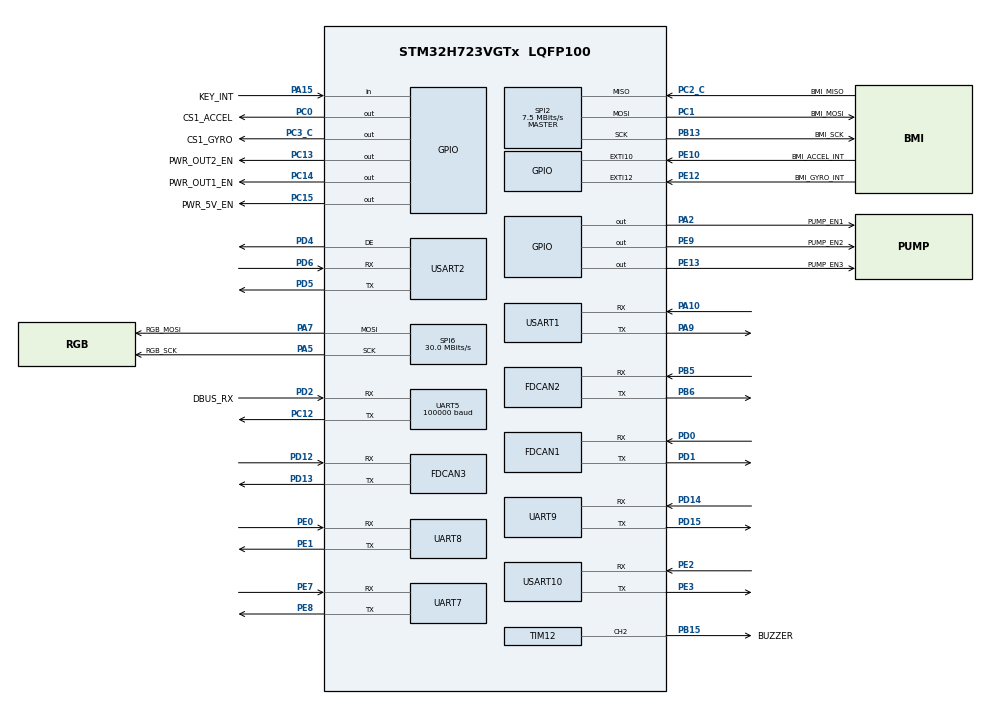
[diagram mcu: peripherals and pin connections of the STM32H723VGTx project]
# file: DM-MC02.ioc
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CORTEX_M7.CPU_DCache=Disabled
CORTEX_M7.CPU_ICache=Enabled
CORTEX_M7.Enable-Cortex_Memory_Protection_Unit_Region0_Settings=MPU_REGION_ENABLE
CORTEX_M7.MPU_Control=__NULL
CORTEX_M7.default_mode_Activation=0
Dma.Request0=SPI2_RX
Dma.Request1=SPI2_TX
Dma.Request10=UART8_TX
Dma.Request11=UART9_RX
Dma.Request12=UART9_TX
Dma.Request2=USART10_RX
Dma.Request3=USART10_TX
Dma.Request4=UART5_RX
Dma.Request5=USART1_RX
Dma.Request6=USART1_TX
Dma.Request7=UART7_RX
Dma.Request8=UART7_TX
Dma.Request9=UART8_RX
Dma.SPI2_RX.0.Direction=DMA_PERIPH_TO_MEMORY
Dma.SPI2_RX.0.EventEnable=DISABLE
Dma.SPI2_RX.0.FIFOMode=DMA_FIFOMODE_DISABLE
Dma.SPI2_RX.0.Instance=DMA1_Stream1
Dma.SPI2_RX.0.MemDataAlignment=DMA_MDATAALIGN_BYTE
Dma.SPI2_RX.0.MemInc=DMA_MINC_ENABLE
Dma.SPI2_RX.0.Mode=DMA_NORMAL
Dma.SPI2_RX.0.PeriphDataAlignment=DMA_PDATAALIGN_BYTE
Dma.SPI2_RX.0.PeriphInc=DMA_PINC_DISABLE
Dma.SPI2_RX.0.Polarity=HAL_DMAMUX_REQ_GEN_RISING
Dma.SPI2_RX.0.Priority=DMA_PRIORITY_VERY_HIGH
Dma.SPI2_RX.0.RequestNumber=1
Dma.SPI2_RX.0.SignalID=NONE
Dma.SPI2_RX.0.SyncEnable=DISABLE
Dma.SPI2_RX.0.SyncPolarity=HAL_DMAMUX_SYNC_NO_EVENT
Dma.SPI2_RX.0.SyncRequestNumber=1
Dma.SPI2_RX.0.SyncSignalID=NONE
Dma.SPI2_TX.1.Direction=DMA_MEMORY_TO_PERIPH
Dma.SPI2_TX.1.EventEnable=DISABLE
Dma.SPI2_TX.1.FIFOMode=DMA_FIFOMODE_DISABLE
Dma.SPI2_TX.1.Instance=DMA1_Stream2
Dma.SPI2_TX.1.MemDataAlignment=DMA_MDATAALIGN_BYTE
Dma.SPI2_TX.1.MemInc=DMA_MINC_ENABLE
Dma.SPI2_TX.1.Mode=DMA_NORMAL
Dma.SPI2_TX.1.PeriphDataAlignment=DMA_PDATAALIGN_BYTE
Dma.SPI2_TX.1.PeriphInc=DMA_PINC_DISABLE
Dma.SPI2_TX.1.Polarity=HAL_DMAMUX_REQ_GEN_RISING
Dma.SPI2_TX.1.Priority=DMA_PRIORITY_MEDIUM
Dma.SPI2_TX.1.RequestNumber=1
Dma.SPI2_TX.1.SignalID=NONE
Dma.SPI2_TX.1.SyncEnable=DISABLE
Dma.SPI2_TX.1.SyncPolarity=HAL_DMAMUX_SYNC_NO_EVENT
Dma.SPI2_TX.1.SyncRequestNumber=1
Dma.SPI2_TX.1.SyncSignalID=NONE
Dma.UART5_RX.4.Direction=DMA_PERIPH_TO_MEMORY
Dma.UART5_RX.4.EventEnable=DISABLE
Dma.UART5_RX.4.FIFOMode=DMA_FIFOMODE_DISABLE
Dma.UART5_RX.4.Instance=DMA1_Stream0
Dma.UART5_RX.4.MemDataAlignment=DMA_MDATAALIGN_BYTE
Dma.UART5_RX.4.MemInc=DMA_MINC_ENABLE
Dma.UART5_RX.4.Mode=DMA_CIRCULAR
Dma.UART5_RX.4.PeriphDataAlignment=DMA_PDATAALIGN_BYTE
Dma.UART5_RX.4.PeriphInc=DMA_PINC_DISABLE
Dma.UART5_RX.4.Polarity=HAL_DMAMUX_REQ_GEN_RISING
Dma.UART5_RX.4.Priority=DMA_PRIORITY_LOW
Dma.UART5_RX.4.RequestNumber=1
Dma.UART5_RX.4.SignalID=NONE
Dma.UART5_RX.4.SyncEnable=DISABLE
Dma.UART5_RX.4.SyncPolarity=HAL_DMAMUX_SYNC_NO_EVENT
Dma.UART5_RX.4.SyncRequestNumber=1
Dma.UART5_RX.4.SyncSignalID=NONE
Dma.UART7_RX.7.Direction=DMA_PERIPH_TO_MEMORY
Dma.UART7_RX.7.EventEnable=DISABLE
Dma.UART7_RX.7.FIFOMode=DMA_FIFOMODE_DISABLE
Dma.UART7_RX.7.Instance=DMA1_Stream7
Dma.UART7_RX.7.MemDataAlignment=DMA_MDATAALIGN_BYTE
Dma.UART7_RX.7.MemInc=DMA_MINC_ENABLE
Dma.UART7_RX.7.Mode=DMA_CIRCULAR
Dma.UART7_RX.7.PeriphDataAlignment=DMA_PDATAALIGN_BYTE
Dma.UART7_RX.7.PeriphInc=DMA_PINC_DISABLE
Dma.UART7_RX.7.Polarity=HAL_DMAMUX_REQ_GEN_RISING
Dma.UART7_RX.7.Priority=DMA_PRIORITY_VERY_HIGH
Dma.UART7_RX.7.RequestNumber=1
Dma.UART7_RX.7.SignalID=NONE
Dma.UART7_RX.7.SyncEnable=DISABLE
Dma.UART7_RX.7.SyncPolarity=HAL_DMAMUX_SYNC_NO_EVENT
Dma.UART7_RX.7.SyncRequestNumber=1
Dma.UART7_RX.7.SyncSignalID=NONE
Dma.UART7_TX.8.Direction=DMA_MEMORY_TO_PERIPH
Dma.UART7_TX.8.EventEnable=DISABLE
Dma.UART7_TX.8.FIFOMode=DMA_FIFOMODE_DISABLE
Dma.UART7_TX.8.Instance=DMA2_Stream0
Dma.UART7_TX.8.MemDataAlignment=DMA_MDATAALIGN_BYTE
Dma.UART7_TX.8.MemInc=DMA_MINC_ENABLE
Dma.UART7_TX.8.Mode=DMA_NORMAL
Dma.UART7_TX.8.PeriphDataAlignment=DMA_PDATAALIGN_BYTE
Dma.UART7_TX.8.PeriphInc=DMA_PINC_DISABLE
Dma.UART7_TX.8.Polarity=HAL_DMAMUX_REQ_GEN_RISING
Dma.UART7_TX.8.Priority=DMA_PRIORITY_VERY_HIGH
Dma.UART7_TX.8.RequestNumber=1
Dma.UART7_TX.8.SignalID=NONE
Dma.UART7_TX.8.SyncEnable=DISABLE
Dma.UART7_TX.8.SyncPolarity=HAL_DMAMUX_SYNC_NO_EVENT
Dma.UART7_TX.8.SyncRequestNumber=1
Dma.UART7_TX.8.SyncSignalID=NONE
Dma.UART8_RX.9.Direction=DMA_PERIPH_TO_MEMORY
Dma.UART8_RX.9.EventEnable=DISABLE
Dma.UART8_RX.9.FIFOMode=DMA_FIFOMODE_DISABLE
Dma.UART8_RX.9.Instance=DMA2_Stream1
Dma.UART8_RX.9.MemDataAlignment=DMA_MDATAALIGN_BYTE
Dma.UART8_RX.9.MemInc=DMA_MINC_ENABLE
Dma.UART8_RX.9.Mode=DMA_CIRCULAR
Dma.UART8_RX.9.PeriphDataAlignment=DMA_PDATAALIGN_BYTE
Dma.UART8_RX.9.PeriphInc=DMA_PINC_DISABLE
Dma.UART8_RX.9.Polarity=HAL_DMAMUX_REQ_GEN_RISING
Dma.UART8_RX.9.Priority=DMA_PRIORITY_VERY_HIGH
Dma.UART8_RX.9.RequestNumber=1
Dma.UART8_RX.9.SignalID=NONE
Dma.UART8_RX.9.SyncEnable=DISABLE
Dma.UART8_RX.9.SyncPolarity=HAL_DMAMUX_SYNC_NO_EVENT
Dma.UART8_RX.9.SyncRequestNumber=1
Dma.UART8_RX.9.SyncSignalID=NONE
Dma.UART8_TX.10.Direction=DMA_MEMORY_TO_PERIPH
Dma.UART8_TX.10.EventEnable=DISABLE
Dma.UART8_TX.10.FIFOMode=DMA_FIFOMODE_DISABLE
Dma.UART8_TX.10.Instance=DMA2_Stream2
Dma.UART8_TX.10.MemDataAlignment=DMA_MDATAALIGN_BYTE
Dma.UART8_TX.10.MemInc=DMA_MINC_ENABLE
Dma.UART8_TX.10.Mode=DMA_NORMAL
Dma.UART8_TX.10.PeriphDataAlignment=DMA_PDATAALIGN_BYTE
Dma.UART8_TX.10.PeriphInc=DMA_PINC_DISABLE
Dma.UART8_TX.10.Polarity=HAL_DMAMUX_REQ_GEN_RISING
Dma.UART8_TX.10.Priority=DMA_PRIORITY_VERY_HIGH
Dma.UART8_TX.10.RequestNumber=1
Dma.UART8_TX.10.SignalID=NONE
Dma.UART8_TX.10.SyncEnable=DISABLE
Dma.UART8_TX.10.SyncPolarity=HAL_DMAMUX_SYNC_NO_EVENT
Dma.UART8_TX.10.SyncRequestNumber=1
Dma.UART8_TX.10.SyncSignalID=NONE
Dma.UART9_RX.11.Direction=DMA_PERIPH_TO_MEMORY
Dma.UART9_RX.11.EventEnable=DISABLE
Dma.UART9_RX.11.FIFOMode=DMA_FIFOMODE_DISABLE
Dma.UART9_RX.11.Instance=DMA2_Stream3
Dma.UART9_RX.11.MemDataAlignment=DMA_MDATAALIGN_BYTE
Dma.UART9_RX.11.MemInc=DMA_MINC_ENABLE
Dma.UART9_RX.11.Mode=DMA_CIRCULAR
Dma.UART9_RX.11.PeriphDataAlignment=DMA_PDATAALIGN_BYTE
Dma.UART9_RX.11.PeriphInc=DMA_PINC_DISABLE
Dma.UART9_RX.11.Polarity=HAL_DMAMUX_REQ_GEN_RISING
Dma.UART9_RX.11.Priority=DMA_PRIORITY_VERY_HIGH
Dma.UART9_RX.11.RequestNumber=1
Dma.UART9_RX.11.SignalID=NONE
Dma.UART9_RX.11.SyncEnable=DISABLE
Dma.UART9_RX.11.SyncPolarity=HAL_DMAMUX_SYNC_NO_EVENT
Dma.UART9_RX.11.SyncRequestNumber=1
Dma.UART9_RX.11.SyncSignalID=NONE
Dma.UART9_TX.12.Direction=DMA_MEMORY_TO_PERIPH
Dma.UART9_TX.12.EventEnable=DISABLE
Dma.UART9_TX.12.FIFOMode=DMA_FIFOMODE_DISABLE
Dma.UART9_TX.12.Instance=DMA2_Stream4
Dma.UART9_TX.12.MemDataAlignment=DMA_MDATAALIGN_BYTE
Dma.UART9_TX.12.MemInc=DMA_MINC_ENABLE
Dma.UART9_TX.12.Mode=DMA_NORMAL
Dma.UART9_TX.12.PeriphDataAlignment=DMA_PDATAALIGN_BYTE
Dma.UART9_TX.12.PeriphInc=DMA_PINC_DISABLE
Dma.UART9_TX.12.Polarity=HAL_DMAMUX_REQ_GEN_RISING
Dma.UART9_TX.12.Priority=DMA_PRIORITY_VERY_HIGH
Dma.UART9_TX.12.RequestNumber=1
Dma.UART9_TX.12.SignalID=NONE
Dma.UART9_TX.12.SyncEnable=DISABLE
Dma.UART9_TX.12.SyncPolarity=HAL_DMAMUX_SYNC_NO_EVENT
Dma.UART9_TX.12.SyncRequestNumber=1
Dma.UART9_TX.12.SyncSignalID=NONE
Dma.USART10_RX.2.Direction=DMA_PERIPH_TO_MEMORY
Dma.USART10_RX.2.EventEnable=DISABLE
Dma.USART10_RX.2.FIFOMode=DMA_FIFOMODE_DISABLE
Dma.USART10_RX.2.Instance=DMA1_Stream5
Dma.USART10_RX.2.MemDataAlignment=DMA_MDATAALIGN_BYTE
Dma.USART10_RX.2.MemInc=DMA_MINC_ENABLE
Dma.USART10_RX.2.Mode=DMA_CIRCULAR
Dma.USART10_RX.2.PeriphDataAlignment=DMA_PDATAALIGN_BYTE
Dma.USART10_RX.2.PeriphInc=DMA_PINC_DISABLE
Dma.USART10_RX.2.Polarity=HAL_DMAMUX_REQ_GEN_RISING
Dma.USART10_RX.2.Priority=DMA_PRIORITY_VERY_HIGH
Dma.USART10_RX.2.RequestNumber=1
Dma.USART10_RX.2.SignalID=NONE
Dma.USART10_RX.2.SyncEnable=DISABLE
Dma.USART10_RX.2.SyncPolarity=HAL_DMAMUX_SYNC_NO_EVENT
Dma.USART10_RX.2.SyncRequestNumber=1
Dma.USART10_RX.2.SyncSignalID=NONE
Dma.USART10_TX.3.Direction=DMA_MEMORY_TO_PERIPH
Dma.USART10_TX.3.EventEnable=DISABLE
Dma.USART10_TX.3.FIFOMode=DMA_FIFOMODE_DISABLE
Dma.USART10_TX.3.Instance=DMA1_Stream6
Dma.USART10_TX.3.MemDataAlignment=DMA_MDATAALIGN_BYTE
Dma.USART10_TX.3.MemInc=DMA_MINC_ENABLE
Dma.USART10_TX.3.Mode=DMA_NORMAL
Dma.USART10_TX.3.PeriphDataAlignment=DMA_PDATAALIGN_BYTE
Dma.USART10_TX.3.PeriphInc=DMA_PINC_DISABLE
Dma.USART10_TX.3.Polarity=HAL_DMAMUX_REQ_GEN_RISING
Dma.USART10_TX.3.Priority=DMA_PRIORITY_VERY_HIGH
Dma.USART10_TX.3.RequestNumber=1
Dma.USART10_TX.3.SignalID=NONE
Dma.USART10_TX.3.SyncEnable=DISABLE
Dma.USART10_TX.3.SyncPolarity=HAL_DMAMUX_SYNC_NO_EVENT
Dma.USART10_TX.3.SyncRequestNumber=1
Dma.USART10_TX.3.SyncSignalID=NONE
Dma.USART1_RX.5.Direction=DMA_PERIPH_TO_MEMORY
Dma.USART1_RX.5.EventEnable=DISABLE
Dma.USART1_RX.5.FIFOMode=DMA_FIFOMODE_DISABLE
Dma.USART1_RX.5.Instance=DMA1_Stream3
Dma.USART1_RX.5.MemDataAlignment=DMA_MDATAALIGN_BYTE
Dma.USART1_RX.5.MemInc=DMA_MINC_ENABLE
Dma.USART1_RX.5.Mode=DMA_NORMAL
Dma.USART1_RX.5.PeriphDataAlignment=DMA_PDATAALIGN_BYTE
Dma.USART1_RX.5.PeriphInc=DMA_PINC_DISABLE
Dma.USART1_RX.5.Polarity=HAL_DMAMUX_REQ_GEN_RISING
Dma.USART1_RX.5.Priority=DMA_PRIORITY_VERY_HIGH
Dma.USART1_RX.5.RequestNumber=1
Dma.USART1_RX.5.SignalID=NONE
Dma.USART1_RX.5.SyncEnable=DISABLE
Dma.USART1_RX.5.SyncPolarity=HAL_DMAMUX_SYNC_NO_EVENT
Dma.USART1_RX.5.SyncRequestNumber=1
Dma.USART1_RX.5.SyncSignalID=NONE
Dma.USART1_TX.6.Direction=DMA_MEMORY_TO_PERIPH
Dma.USART1_TX.6.EventEnable=DISABLE
Dma.USART1_TX.6.FIFOMode=DMA_FIFOMODE_DISABLE
Dma.USART1_TX.6.Instance=DMA1_Stream4
Dma.USART1_TX.6.MemDataAlignment=DMA_MDATAALIGN_BYTE
Dma.USART1_TX.6.MemInc=DMA_MINC_ENABLE
Dma.USART1_TX.6.Mode=DMA_NORMAL
Dma.USART1_TX.6.PeriphDataAlignment=DMA_PDATAALIGN_BYTE
Dma.USART1_TX.6.PeriphInc=DMA_PINC_DISABLE
Dma.USART1_TX.6.Polarity=HAL_DMAMUX_REQ_GEN_RISING
Dma.USART1_TX.6.Priority=DMA_PRIORITY_VERY_HIGH
Dma.USART1_TX.6.RequestNumber=1
Dma.USART1_TX.6.SignalID=NONE
Dma.USART1_TX.6.SyncEnable=DISABLE
Dma.USART1_TX.6.SyncPolarity=HAL_DMAMUX_SYNC_NO_EVENT
Dma.USART1_TX.6.SyncRequestNumber=1
Dma.USART1_TX.6.SyncSignalID=NONE
FDCAN1.AutoRetransmission=ENABLE
FDCAN1.CalculateBaudRateNominal=1000000
FDCAN1.CalculateTimeBitNominal=1000
FDCAN1.CalculateTimeQuantumNominal=50.0
FDCAN1.ClockCalibrationCCU=DISABLE
FDCAN1.DataPrescaler=5
FDCAN1.DataTimeSeg1=14
FDCAN1.DataTimeSeg2=5
FDCAN1.ExtFiltersNbr=5
FDCAN1.MessageRAMOffset=0
FDCAN1.NominalPrescaler=5
FDCAN1.NominalTimeSeg1=14
FDCAN1.NominalTimeSeg2=5
FDCAN1.RxFifo0ElmtSize=FDCAN_DATA_BYTES_8
FDCAN1.RxFifo0ElmtsNbr=32
FDCAN1.RxFifo1ElmtSize=FDCAN_DATA_BYTES_24
FDCAN1.StdFiltersNbr=5
FDCAN1.TxElmtSize=FDCAN_DATA_BYTES_8
FDCAN1.TxFifoQueueElmtsNbr=32
FDCAN2.AutoRetransmission=ENABLE
FDCAN2.CalculateBaudRateNominal=1000000
FDCAN2.CalculateTimeBitNominal=1000
FDCAN2.CalculateTimeQuantumNominal=50.0
FDCAN2.DataPrescaler=5
FDCAN2.DataTimeSeg1=14
FDCAN2.DataTimeSeg2=5
FDCAN2.ExtFiltersNbr=5
FDCAN2.MessageRAMOffset=1280
FDCAN2.NominalPrescaler=5
FDCAN2.NominalTimeSeg1=14
FDCAN2.NominalTimeSeg2=5
FDCAN2.RxFifo0ElmtSize=FDCAN_DATA_BYTES_8
FDCAN2.RxFifo0ElmtsNbr=32
FDCAN2.RxFifo1ElmtSize=FDCAN_DATA_BYTES_8
FDCAN2.RxFifo1ElmtsNbr=0
FDCAN2.StdFiltersNbr=5
FDCAN2.TxElmtSize=FDCAN_DATA_BYTES_8
FDCAN2.TxFifoQueueElmtsNbr=8
FDCAN3.AutoRetransmission=ENABLE
FDCAN3.CalculateBaudRateNominal=1000000
FDCAN3.CalculateTimeBitNominal=1000
FDCAN3.CalculateTimeQuantumNominal=50.0
FDCAN3.DataPrescaler=5
FDCAN3.DataTimeSeg1=14
FDCAN3.DataTimeSeg2=5
FDCAN3.ExtFiltersNbr=5
FDCAN3.MessageRAMOffset=1709
FDCAN3.NominalPrescaler=5
FDCAN3.NominalTimeSeg1=14
FDCAN3.NominalTimeSeg2=5
FDCAN3.RxFifo0ElmtsNbr=0
FDCAN3.RxFifo1ElmtsNbr=32
FDCAN3.StdFiltersNbr=5
FDCAN3.TxFifoQueueElmtsNbr=20
FREERTOS.Tasks01=MonitorTask,32,512,StartMonitorTask,As weak,NULL,Dynamic,NULL,NULL;CtrlTask,32,512,StartCtrlTask,As weak,NULL,Dynamic,NULL,NULL;CommandTask,40,256,StartCommandTask,As weak,NULL,Dynamic,NULL,NULL;UpdataTask,16,256,StartUpdataTask,As weak,NULL,Dynamic,NULL,NULL;UITask,16,1024,StartUITask,As weak,NULL,Dynamic,NULL,NULL
Mcu.Family=STM32H7
Mcu.Name=STM32H723VGTx
Mcu.Package=LQFP100
NVIC.DMA1_Stream0_IRQn=true\:5\:0\:false\:false\:true\:true\:false\:true\:true
NVIC.DMA1_Stream1_IRQn=true\:5\:0\:true\:false\:true\:true\:false\:true\:true
NVIC.DMA1_Stream2_IRQn=true\:5\:0\:true\:false\:true\:true\:false\:true\:true
NVIC.DMA1_Stream3_IRQn=true\:0\:0\:true\:false\:true\:false\:false\:true\:true
NVIC.DMA1_Stream4_IRQn=true\:0\:0\:true\:false\:true\:false\:false\:true\:true
NVIC.DMA1_Stream5_IRQn=true\:0\:0\:true\:false\:true\:false\:false\:true\:true
NVIC.DMA1_Stream6_IRQn=true\:0\:0\:true\:false\:true\:false\:false\:true\:true
NVIC.DMA1_Stream7_IRQn=true\:0\:0\:true\:false\:true\:false\:false\:true\:true
NVIC.DMA2_Stream0_IRQn=true\:0\:0\:true\:false\:true\:false\:false\:true\:true
NVIC.DMA2_Stream1_IRQn=true\:5\:0\:false\:false\:true\:false\:false\:true\:true
NVIC.DMA2_Stream2_IRQn=true\:5\:0\:false\:false\:true\:false\:false\:true\:true
NVIC.DMA2_Stream3_IRQn=true\:5\:0\:false\:false\:true\:false\:false\:true\:true
NVIC.DMA2_Stream4_IRQn=true\:5\:0\:false\:false\:true\:false\:false\:true\:true
NVIC.EXTI15_10_IRQn=true\:5\:0\:true\:false\:true\:true\:true\:true\:true
NVIC.FDCAN1_IT0_IRQn=true\:5\:0\:true\:false\:true\:true\:true\:true\:true
NVIC.FDCAN2_IT0_IRQn=true\:5\:0\:true\:false\:true\:true\:true\:true\:true
NVIC.FDCAN3_IT0_IRQn=true\:5\:0\:true\:false\:true\:true\:true\:true\:true
NVIC.PriorityGroup=NVIC_PRIORITYGROUP_4
NVIC.SPI2_IRQn=true\:5\:0\:true\:false\:true\:true\:true\:true\:true
NVIC.SPI6_IRQn=true\:5\:0\:true\:false\:true\:true\:true\:true\:true
NVIC.TIM2_IRQn=true\:15\:0\:false\:false\:true\:false\:false\:true\:true
NVIC.TimeBase=TIM2_IRQn
NVIC.TimeBaseIP=TIM2
NVIC.UART5_IRQn=true\:5\:0\:false\:false\:true\:true\:true\:true\:true
NVIC.UART7_IRQn=true\:5\:0\:false\:false\:true\:true\:true\:true\:true
NVIC.UART8_IRQn=true\:5\:0\:false\:false\:true\:true\:true\:true\:true
NVIC.UART9_IRQn=true\:5\:0\:false\:false\:true\:true\:true\:true\:true
NVIC.USART10_IRQn=true\:5\:0\:false\:false\:true\:true\:true\:true\:true
NVIC.USART1_IRQn=true\:5\:0\:false\:false\:true\:true\:true\:true\:true
PA0.GPIO_Label=GIMB_PITCH_PWM
PA0.Signal=S_TIM2_CH1_ETR
PA10.Mode=Asynchronous
PA10.Signal=USART1_RX
PA13(JTMS/SWDIO).GPIO_Label=SWDIO
PA13(JTMS/SWDIO).Mode=Serial_Wire
PA13(JTMS/SWDIO).Signal=DEBUG_JTMS-SWDIO
PA14(JTCK/SWCLK).GPIO_Label=SWCLK
PA14(JTCK/SWCLK).Mode=Serial_Wire
PA14(JTCK/SWCLK).Signal=DEBUG_JTCK-SWCLK
PA15(JTDI).GPIO_Label=KEY_INT
PA15(JTDI).Signal=GPIO_Input
PA2.GPIO_Label=PUMP_EN1
PA2.GPIO_PuPd=GPIO_PULLDOWN
PA2.Signal=GPIO_Output
PA5.GPIO_Label=RGB_SCK
PA5.Mode=TX_Only_Simplex_Unidirect_Master
PA5.Signal=SPI6_SCK
PA7.GPIO_Label=RGB_MOSI
PA7.Mode=TX_Only_Simplex_Unidirect_Master
PA7.Signal=SPI6_MOSI
PA9.Mode=Asynchronous
PA9.Signal=USART1_TX
PB1.GPIO_Label=BMI_TEMP_PWM
PB1.Signal=S_TIM3_CH4
PB13.GPIO_Label=BMI_SCK
PB13.Mode=Full_Duplex_Master
PB13.Signal=SPI2_SCK
PB14.Signal=USART3_DE
PB15.GPIO_Label=BUZZER
PB15.Signal=S_TIM12_CH2
PB5.Mode=FDCAN_Activate
PB5.Signal=FDCAN2_RX
PB6.Mode=FDCAN_Activate
PB6.Signal=FDCAN2_TX
PC0.GPIO_Label=CS1_ACCEL
PC0.GPIO_Speed=GPIO_SPEED_FREQ_VERY_HIGH
PC0.PinState=GPIO_PIN_SET
PC0.Signal=GPIO_Output
PC1.GPIO_Label=BMI_MOSI
PC1.Mode=Full_Duplex_Master
PC1.Signal=SPI2_MOSI
PC12.Mode=Asynchronous
PC12.Signal=UART5_TX
PC13.GPIO_Label=PWR_OUT2_EN
PC13.Signal=GPIO_Output
PC14-OSC32_IN.GPIO_Label=PWR_OUT1_EN
PC14-OSC32_IN.Signal=GPIO_Output
PC15-OSC32_OUT.GPIO_Label=PWR_5V_EN
PC15-OSC32_OUT.PinState=GPIO_PIN_SET
PC15-OSC32_OUT.Signal=GPIO_Output
PC2_C.GPIO_Label=BMI_MISO
PC2_C.Mode=Full_Duplex_Master
PC2_C.Signal=SPI2_MISO
PC3_C.GPIO_Label=CS1_GYRO
PC3_C.GPIO_Speed=GPIO_SPEED_FREQ_VERY_HIGH
PC3_C.PinState=GPIO_PIN_SET
PC3_C.Signal=GPIO_Output
PD0.Mode=FDCAN_Activate
PD0.Signal=FDCAN1_RX
PD1.Mode=FDCAN_Activate
PD1.Signal=FDCAN1_TX
PD12.Mode=FDCAN_Activate
PD12.Signal=FDCAN3_RX
PD13.Mode=FDCAN_Activate
PD13.Signal=FDCAN3_TX
PD14.Mode=Asynchronous
PD14.Signal=UART9_RX
PD15.Mode=Asynchronous
PD15.Signal=UART9_TX
PD2.GPIO_Label=DBUS_RX
PD2.Mode=Asynchronous
PD2.Signal=UART5_RX
PD4.Mode=Hardware Flow Control (RS485)
PD4.Signal=USART2_DE
PD5.Mode=Asynchronous
PD5.Signal=USART2_TX
PD6.Mode=Asynchronous
PD6.Signal=USART2_RX
PD8.Signal=USART3_TX
PD9.Signal=USART3_RX
PE0.Mode=Asynchronous
PE0.Signal=UART8_RX
PE1.Mode=Asynchronous
PE1.Signal=UART8_TX
PE10.GPIO_Label=BMI_ACCEL_INT
PE10.Signal=GPXTI10
PE12.GPIO_Label=BMI_GYRO_INT
PE12.Signal=GPXTI12
PE13.GPIO_Label=PUMP_EN3
PE13.GPIO_PuPd=GPIO_PULLDOWN
PE13.Signal=GPIO_Output
PE2.Mode=Asynchronous
PE2.Signal=USART10_RX
PE3.Mode=Asynchronous
PE3.Signal=USART10_TX
PE7.Mode=Asynchronous
PE7.Signal=UART7_RX
PE8.Mode=Asynchronous
PE8.Signal=UART7_TX
PE9.GPIO_Label=PUMP_EN2
PE9.GPIO_PuPd=GPIO_PULLDOWN
PE9.Signal=GPIO_Output
PH0-OSC_IN.Mode=HSE-External-Oscillator
PH0-OSC_IN.Signal=RCC_OSC_IN
PH1-OSC_OUT.Mode=HSE-External-Oscillator
PH1-OSC_OUT.Signal=RCC_OSC_OUT
ProjectManager.HeapSize=0x400
ProjectManager.StackSize=0x400
ProjectManager.TargetToolchain=MDK-ARM V5.32
RCC.ADCFreq_Value=50000000
RCC.APB1Freq_Value=120000000
RCC.APB2Freq_Value=120000000
RCC.APB3Freq_Value=120000000
RCC.APB4Freq_Value=120000000
RCC.CortexFreq_Value=480000000
RCC.D1PPRE=RCC_APB3_DIV2
RCC.D2PPRE1=RCC_APB1_DIV2
RCC.D2PPRE2=RCC_APB2_DIV2
RCC.D3PPRE=RCC_APB4_DIV2
RCC.DIVM1=2
RCC.DIVM2=24
RCC.DIVN1=40
RCC.DIVN2=200
RCC.DIVP1=1
RCC.DIVP2=4
RCC.FDCANCLockSelection=RCC_FDCANCLKSOURCE_PLL2
RCC.HCLKFreq_Value=240000000
RCC.HPRE=RCC_HCLK_DIV2
RCC.HSE_VALUE=24000000
RCC.PLL1_VCO_SEL-AdvancedSettings=RCC_PLL1VCOWIDE
RCC.PLL2FRACN=0
RCC.PLL3FRACN=0
RCC.PLL3_VCO_SEL-AdvancedSettings=RCC_PLL3VCOMEDIUM
RCC.PLLFRACN=0
RCC.PLLSourceVirtual=RCC_PLLSOURCE_HSE
RCC.QSPICLockSelection=RCC_OSPICLKSOURCE_PLL2
RCC.SYSCLKFreq_VALUE=480000000
RCC.SYSCLKSource=RCC_SYSCLKSOURCE_PLLCLK
RCC.Tim2Mul=1
RCC.USBCLockSelection=RCC_USBCLKSOURCE_PLL3
RCC.USBFreq_Value=48375000
SH.S_TIM12_CH2.0=TIM12_CH2,PWM Generation2 CH2
SH.S_TIM2_CH1_ETR.0=TIM2_CH1
SH.S_TIM3_CH4.0=TIM3_CH4
SPI2.BaudRatePrescaler=SPI_BAUDRATEPRESCALER_32
SPI2.CLKPhase=SPI_PHASE_2EDGE
SPI2.CLKPolarity=SPI_POLARITY_HIGH
SPI2.CalculateBaudRate=7.5 MBits/s
SPI2.DataSize=SPI_DATASIZE_8BIT
SPI2.Direction=SPI_DIRECTION_2LINES
SPI2.Mode=SPI_MODE_MASTER
SPI2.NSSPMode=SPI_NSS_PULSE_DISABLE
SPI2.VirtualType=VM_MASTER
SPI6.BaudRatePrescaler=SPI_BAUDRATEPRESCALER_4
SPI6.CLKPhase=SPI_PHASE_2EDGE
SPI6.CalculateBaudRate=30.0 MBits/s
SPI6.DataSize=SPI_DATASIZE_8BIT
SPI6.Direction=SPI_DIRECTION_2LINES_TXONLY
SPI6.Mode=SPI_MODE_MASTER
SPI6.VirtualType=VM_MASTER
TIM12.Channel-PWM\ Generation2\ CH2=TIM_CHANNEL_2
TIM12.Period=2000-1
TIM12.Prescaler=24-1
TIM12.Pulse-PWM\ Generation2\ CH2=1000
UART5.BaudRate=100000
UART5.Mode=MODE_RX
UART5.Parity=PARITY_EVEN
UART5.StopBits=UART_STOPBITS_2
UART5.WordLength=WORDLENGTH_9B
USART1.VirtualMode-Asynchronous=VM_ASYNC
USART10.VirtualMode=VM_ASYNC
USART2.VirtualMode-Asynchronous=VM_ASYNC
USART2.VirtualMode-Hardware\ Flow\ Control\ (RS485)=VM_ASYNC
VP_FREERTOS_VS_CMSIS_V2.Mode=CMSIS_V2
VP_MEMORYMAP_VS_MEMORYMAP.Mode=CurAppReg
VP_SYS_VS_tim2.Mode=TIM2
board=custom

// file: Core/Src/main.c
/* USER CODE BEGIN Header */
/**
  ******************************************************************************
  * @file           : main.c
  * @brief          : Main program body
  ******************************************************************************
  * @attention
  *
  * Copyright (c) 2025 STMicroelectronics.
  * All rights reserved.
  *
  * This software is licensed under terms that can be found in the LICENSE file
  * in the root directory of this software component.
  * If no LICENSE file comes with this software, it is provided AS-IS.
  *
  ******************************************************************************
  */
/* USER CODE END Header */
#include "main.h"
#include "FreeRTOS.h"
#include "cmsis_os2.h"
#include "dma.h"
#include "fdcan.h"
#include "spi.h"
#include "tim.h"
#include "usart.h"
#include "gpio.h"

/* USER CODE BEGIN Includes */
#include "device.h"
#include "driver.h"
/* USER CODE END Includes */

void SystemClock_Config(void);
void PeriphCommonClock_Config(void);
void MX_FREERTOS_Init(void);

int main(void)
{

  /* Enable the CPU Cache */

  /* Enable I-Cache---------------------------------------------------------*/
  SCB_EnableICache();

  /* MCU Configuration--------------------------------------------------------*/

  /* Reset of all peripherals, Initializes the Flash interface and the Systick. */
  HAL_Init();

  /* Configure the system clock */
  SystemClock_Config();

  /* Configure the peripherals common clocks */
  PeriphCommonClock_Config();

  /* Initialize all configured peripherals */
  MX_GPIO_Init();
  MX_DMA_Init();
  MX_SPI2_Init();
  MX_FDCAN1_Init();
  MX_SPI6_Init();
  MX_TIM12_Init();
  MX_USART2_UART_Init();
  MX_FDCAN2_Init();
  MX_FDCAN3_Init();
  MX_USART10_UART_Init();
  MX_UART5_Init();
  MX_UART7_Init();
  MX_USART1_UART_Init();
  MX_UART8_Init();
  MX_UART9_Init();
  /* USER CODE BEGIN 2 */
	/*CubeMX�����ʼ��UART5Ҫ��SPI2��ң�ز�������ʹ�ã���Ҫʹ��D-Cache*/
	DEVICE_Init();
	DRIVER_Init();

  /* USER CODE END 2 */

  /* Init scheduler */
  osKernelInitialize();  /* Call init function for freertos objects (in cmsis_os2.c) */
  MX_FREERTOS_Init();

  /* Start scheduler */
  osKernelStart();

  /* We should never get here as control is now taken by the scheduler */

  /* Infinite loop */
  while (1)
  {

  }
}

void SystemClock_Config(void)
{
  RCC_OscInitTypeDef RCC_OscInitStruct = {0};
  RCC_ClkInitTypeDef RCC_ClkInitStruct = {0};

  /** Supply configuration update enable
  */
  HAL_PWREx_ConfigSupply(PWR_LDO_SUPPLY);

  /** Configure the main internal regulator output voltage
  */
  __HAL_PWR_VOLTAGESCALING_CONFIG(PWR_REGULATOR_VOLTAGE_SCALE0);

  while(!__HAL_PWR_GET_FLAG(PWR_FLAG_VOSRDY)) {}

  /** Initializes the RCC Oscillators according to the specified parameters
  * in the RCC_OscInitTypeDef structure.
  */
  RCC_OscInitStruct.OscillatorType = RCC_OSCILLATORTYPE_HSE;
  RCC_OscInitStruct.HSEState = RCC_HSE_ON;
  RCC_OscInitStruct.PLL.PLLState = RCC_PLL_ON;
  RCC_OscInitStruct.PLL.PLLSource = RCC_PLLSOURCE_HSE;
  RCC_OscInitStruct.PLL.PLLM = 2;
  RCC_OscInitStruct.PLL.PLLN = 40;
  RCC_OscInitStruct.PLL.PLLP = 1;
  RCC_OscInitStruct.PLL.PLLQ = 2;
  RCC_OscInitStruct.PLL.PLLR = 2;
  RCC_OscInitStruct.PLL.PLLRGE = RCC_PLL1VCIRANGE_3;
  RCC_OscInitStruct.PLL.PLLVCOSEL = RCC_PLL1VCOWIDE;
  RCC_OscInitStruct.PLL.PLLFRACN = 0;
  if (HAL_RCC_OscConfig(&RCC_OscInitStruct) != HAL_OK)
  {
    Error_Handler();
  }

  /** Initializes the CPU, AHB and APB buses clocks
  */
  RCC_ClkInitStruct.ClockType = RCC_CLOCKTYPE_HCLK|RCC_CLOCKTYPE_SYSCLK
                              |RCC_CLOCKTYPE_PCLK1|RCC_CLOCKTYPE_PCLK2
                              |RCC_CLOCKTYPE_D3PCLK1|RCC_CLOCKTYPE_D1PCLK1;
  RCC_ClkInitStruct.SYSCLKSource = RCC_SYSCLKSOURCE_PLLCLK;
  RCC_ClkInitStruct.SYSCLKDivider = RCC_SYSCLK_DIV1;
  RCC_ClkInitStruct.AHBCLKDivider = RCC_HCLK_DIV2;
  RCC_ClkInitStruct.APB3CLKDivider = RCC_APB3_DIV2;
  RCC_ClkInitStruct.APB1CLKDivider = RCC_APB1_DIV2;
  RCC_ClkInitStruct.APB2CLKDivider = RCC_APB2_DIV2;
  RCC_ClkInitStruct.APB4CLKDivider = RCC_APB4_DIV2;

  if (HAL_RCC_ClockConfig(&RCC_ClkInitStruct, FLASH_LATENCY_3) != HAL_OK)
  {
    Error_Handler();
  }
}

void PeriphCommonClock_Config(void)
{
  RCC_PeriphCLKInitTypeDef PeriphClkInitStruct = {0};

  /** Initializes the peripherals clock
  */
  PeriphClkInitStruct.PeriphClockSelection = RCC_PERIPHCLK_FDCAN;
  PeriphClkInitStruct.PLL2.PLL2M = 24;
  PeriphClkInitStruct.PLL2.PLL2N = 200;
  PeriphClkInitStruct.PLL2.PLL2P = 4;
  PeriphClkInitStruct.PLL2.PLL2Q = 2;
  PeriphClkInitStruct.PLL2.PLL2R = 2;
  PeriphClkInitStruct.PLL2.PLL2RGE = RCC_PLL2VCIRANGE_0;
  PeriphClkInitStruct.PLL2.PLL2VCOSEL = RCC_PLL2VCOMEDIUM;
  PeriphClkInitStruct.PLL2.PLL2FRACN = 0;
  PeriphClkInitStruct.FdcanClockSelection = RCC_FDCANCLKSOURCE_PLL2;
  if (HAL_RCCEx_PeriphCLKConfig(&PeriphClkInitStruct) != HAL_OK)
  {
    Error_Handler();
  }
}

void HAL_TIM_PeriodElapsedCallback(TIM_HandleTypeDef *htim)
{
  if (htim->Instance == TIM2)
  {
    HAL_IncTick();
  }
}

void Error_Handler(void)
{
  __disable_irq();
  while (1)
  {
  }
}

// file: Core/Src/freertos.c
/* USER CODE BEGIN Header */
/**
  ******************************************************************************
  * File Name          : freertos.c
  * Description        : Code for freertos applications
  ******************************************************************************
  * @attention
  *
  * Copyright (c) 2025 STMicroelectronics.
  * All rights reserved.
  *
  * This software is licensed under terms that can be found in the LICENSE file
  * in the root directory of this software component.
  * If no LICENSE file comes with this software, it is provided AS-IS.
  *
  ******************************************************************************
  */
/* USER CODE END Header */

#include "FreeRTOS.h"
#include "task.h"
#include "main.h"
#include "FreeRTOS.h"
#include "cmsis_os2.h"

/* Definitions for MonitorTask */
osThreadId_t MonitorTaskHandle;
const osThreadAttr_t MonitorTask_attributes = {
  .name = "MonitorTask",
  .stack_size = 512 * 4,
  .priority = (osPriority_t) osPriorityAboveNormal,
};
/* Definitions for CtrlTask */
osThreadId_t CtrlTaskHandle;
const osThreadAttr_t CtrlTask_attributes = {
  .name = "CtrlTask",
  .stack_size = 512 * 4,
  .priority = (osPriority_t) osPriorityAboveNormal,
};
/* Definitions for CommandTask */
osThreadId_t CommandTaskHandle;
const osThreadAttr_t CommandTask_attributes = {
  .name = "CommandTask",
  .stack_size = 256 * 4,
  .priority = (osPriority_t) osPriorityHigh,
};
/* Definitions for UpdataTask */
osThreadId_t UpdataTaskHandle;
const osThreadAttr_t UpdataTask_attributes = {
  .name = "UpdataTask",
  .stack_size = 256 * 4,
  .priority = (osPriority_t) osPriorityBelowNormal,
};
/* Definitions for UITask */
osThreadId_t UITaskHandle;
const osThreadAttr_t UITask_attributes = {
  .name = "UITask",
  .stack_size = 1024 * 4,
  .priority = (osPriority_t) osPriorityBelowNormal,
};

void StartMonitorTask(void *argument);
void StartCtrlTask(void *argument);
void StartCommandTask(void *argument);
void StartUpdataTask(void *argument);
void StartUITask(void *argument);

void MX_FREERTOS_Init(void); /* (MISRA C 2004 rule 8.1) */

void MX_FREERTOS_Init(void) {

  /* Create the thread(s) */
  /* creation of MonitorTask */
  MonitorTaskHandle = osThreadNew(StartMonitorTask, NULL, &MonitorTask_attributes);

  /* creation of CtrlTask */
  CtrlTaskHandle = osThreadNew(StartCtrlTask, NULL, &CtrlTask_attributes);

  /* creation of CommandTask */
  CommandTaskHandle = osThreadNew(StartCommandTask, NULL, &CommandTask_attributes);

  /* creation of UpdataTask */
  UpdataTaskHandle = osThreadNew(StartUpdataTask, NULL, &UpdataTask_attributes);

  /* creation of UITask */
  UITaskHandle = osThreadNew(StartUITask, NULL, &UITask_attributes);

}

__weak void StartMonitorTask(void *argument)
{
  for(;;)
  {
    osDelay(1);
  }
}

__weak void StartCtrlTask(void *argument)
{
  for(;;)
  {
    osDelay(1);
  }
}

__weak void StartCommandTask(void *argument)
{
  for(;;)
  {
    osDelay(1);
  }
}

__weak void StartUpdataTask(void *argument)
{
  for(;;)
  {
    osDelay(1);
  }
}

__weak void StartUITask(void *argument)
{
  for(;;)
  {
    osDelay(1);
  }
}
